# M2354 register map
File version: 1.0
Registers are 32-bit, read-write, reset 0x0 unless marked. A register's access mark holds for its fields unless they carry their own. Offsets are from the block's base; [hi:lo] are bit positions.

## CRC_NS — CRC Register Map
Base 0x50031000
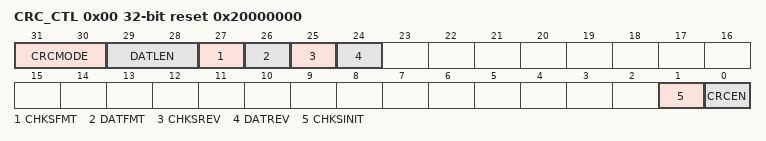
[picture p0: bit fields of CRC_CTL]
0x00 CRC_CTL reset 0x20000000 — CRC Control Register
  [31:30] CRCMODE — CRC Polynomial Mode. This field indicates the CRC operation polynomial mode.
    0=CRC-CCITT Polynomial mode; 1=CRC-8 Polynomial mode; 2=CRC-16 Polynomial mode; 3=CRC-32 Polynomial mode
  [29:28] DATLEN — CPU Write Data Length. This field indicates the write data length. Note: When the write data length is 8-bit mode, the valid data in CRC_DAT register is only DATA[7:0] bits; if the write data length is 16-bit mode, the valid data in CRC_DAT register is only DATA[15:0].
    0=Data length is 8-bit mode; 1=Data length is 16-bit mode. Data length is 32-bit mode
  [27] CHKSFMT — Checksum 1's Complement. This bit is used to enable the 1's complement function for checksum result in CRC_CHECKSUM register.
    0=1's complement for CRC checksum Disabled; 1=1's complement for CRC checksum Enabled
  [26] DATFMT — Write Data 1's Complement. This bit is used to enable the 1's complement function for write data value in CRC_DAT register.
    0=1's complement for CRC writes data in Disabled; 1=1's complement for CRC writes data in Enabled
  [25] CHKSREV — Checksum Bit Order Reverse. This bit is used to enable the bit order reverse function for checksum result in CRC_CHECKSUM register. Note: If the checksum result is 0xDD7B0F2E, the bit order reverse for CRC checksum is 0x74F0DEBB.
    0=Bit order reverse for CRC checksum Disabled; 1=Bit order reverse for CRC checksum Enabled
  [24] DATREV — Write Data Bit Order Reverse. This bit is used to enable the bit order reverse function per byte for write data value in CRC_DAT register. Note: If the write data is 0xAABBCCDD, the bit order reverse for CRC write data in is 0x55DD33BB.
    0=Bit order reversed for CRC write data in Disabled; 1=Bit order reversed for CRC write data in Enabled (per byte)
  [1] CHKSINIT — Checksum Initialization. Note: This bit will be cleared automatically.
    0=No effect; 1=Initial checksum value by auto reload CRC_SEED register value to CRC_CHECKSUM register value
  [0] CRCEN — CRC Channel Enable Bit
    0=No effect; 1=CRC operation Enabled
0x04 CRC_DAT — CRC Write Data Register
  [31:0] DATA — CRC Write Data Bits. User can write data directly by CPU mode or use PDMA function to write data to this field to perform CRC operation. Note: When the write data length is 8-bit mode, the valid data in CRC_DAT register is only DATA[7:0] bits; if the write data length is 16-bit mode, the valid data in CRC_DAT register is only DATA[15:0].
0x08 CRC_SEED reset 0xFFFFFFFF
  [31:0] SEED — CRC Seed Value. This field indicates the CRC seed value. Note: This field will be reloaded as checksum initial value (CRC_CHECKSUM register) after perform CHKSINIT (CRC_CTL[1]).
0x0C CRC_CHECKSUM ro reset 0xFFFFFFFF
  [31:0] CHECKSUM — CRC Checksum Results. This field indicates the CRC checksum result. Note: Data in CRC_CHECKSUM register has different length when user chooses different operation polynomial modes. For example: If final checksum result is 0x12 in CRC-8 polynomial mode, the CHECKSUM[31:0] value will be read as 0x12121212, only CHECKSUM[7:0] is valid in this mode. If final checksum result is 0x1234 in CRC-CCITT or CRC-16 mode, the CHECKSUM[31:0] value will be read as 0x12341234, only CHECKSUM[15:0] is valid in this mode. And the CHECKSUM[31:0] is valid for CRC-32 mode.

## TRNG_NS — TRNG Register Map
Base 0x500B9000
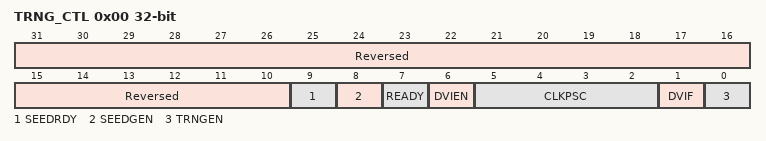
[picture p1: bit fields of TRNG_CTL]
0x00 TRNG_CTL — TRNG Control Register and Status
  [31:10] Reversed
  [9] SEEDRDY ro — Random Number Seed Ready (Read Only) [for TRNG+PRNG]. Note 1: This bit is cleared to '0' when SEEDGEN is 1. Note 2: If SEEDRDY becomes 1, then SEEDGEN will be cleared to 0.
    0=Seed is not ready or not activated; 1=Seed is ready for PRNG
  [8] SEEDGEN — Random Number Seed Generator Enable Bit [for TRNG+PRNG]. This bit can be set to 1 only after ACT (TRNG_ACT[7]) bit is set to 1 and READY (TRNG_CTL[7]) bit becomes 1. Note: If users want to execute TRNG+PRNG mode, they should set SEEDGEN to 1. When SEEDGEN is set to 1, users cannot read the data from TRNG Data Register.
    0=Seed generator Disabled; 1=Seed generator Enabled
  [7] READY ro — Random Number Generator Ready (Read Only). After ACT (TRNG_ACT[7]) bit is set, the READY bit becomes 1 after a delay of 90us~120us.
    0=RNG is not ready or not activated; 1=RNG is ready to be enabled
  [6] DVIEN — Data Valid Interrupt Enable Bit
    0=Interrupt Disabled; 1=Interrupt Enabled
  [5:2] CLKPSC — Clock Prescaler. The CLKP is the peripheral clock frequency range for the selected value. The CLKP must be higher than or equal to the actual peripheral clock frequency (for correct random bit generation). To change the CLKP contents, first set TRNGEN bit to 0 and then change CLKP; finally, set TRNGEN bit to 1 to re-enable the TRNG module.
    0=80 ~ 100 MHz; 1=60 ~ 80 MHz; 2=50 ~60 MHz; 3=40 ~50 MHz; 4=30 ~40 MHz; 5=25 ~30 MHz; 6=20 ~25 MHz; 7=15 ~20 MHz; 8=12 ~15 MHz; 9=9 ~12 MHz; 10=7 ~9 MHz; 11=6 ~7 MHz; 12=5 ~6 MHz; 13=4 ~5 MHz
  [1] DVIF ro — Data Valid (Read Only). Note: This bit is cleared to '0' by reading TRNG_DATA.
    0=Data is not valid. Reading from RNGD returns 0x00000000; 1=Data is valid. A valid random number can be read form RNGD
  [0] TRNGEN — Random Number Generator Enable Bit. This bit can be set to 1 only after ACT (TRNG_ACT[7]) bit is set to 1 and READY (TRNG_CTL[7]) bit becames 1. Note: TRNGEN is an enable bit of digital part. When TRNG is not required to generate random number, TRNGEN bit and ACT (TRNG_ACT[7]) bit should be set to 0 to reduce power consumption.
    0=TRNG Disabled; 1=TRNG Enabled
0x04 TRNG_DATA ro
  [7:0] DATA — Random Number Generator Data (Read Only). The DATA stores the random number generated by TRNG and can be read only once.
0x0C TRNG_ACT reset 0x2 — TRNG Activation Register
  [7] ACT — Random Number Generator Activation. After enabling the ACT bit, it will activate the TRNG module and wait the READY (TRNG_CTL[7]) bit to become 1. Note: ACT is an enable bit of analog part. When TRNG is not required to generate random number, TRNGEN (TRNG_CTL[0]) bit and ACT bit should be set to 0 to reduce power consumption.
    0=TRNG inactive; 1=TRNG active
